# S1C31D50 register map
Vendor: Epson; Series: S1C31D50; File version: 1.00
CPU: CM0PLUS r0p1, little endian, MPU, no FPU, VTOR, 2 interrupt priority bits
Registers are 16-bit, read-write, reset 0x0 unless marked. A register's access mark holds for its fields unless they carry their own. Offsets are from the block's base; [hi:lo] are bit positions; {n}, {i} and the like mark numbered series; 'fields as' and 'values as' point back to an identical list.

## SPIA_0 — Synchronous serial interface control
Base 0x002003B0
Same registers: SPIA_2 0x002004D0, SPIA_1 0x00200670
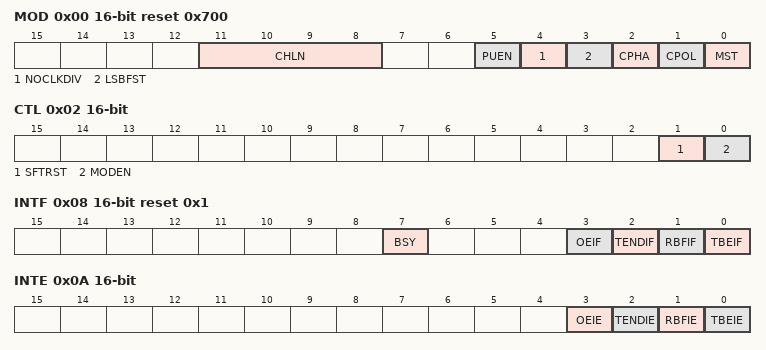
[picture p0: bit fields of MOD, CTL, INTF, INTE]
0x00 MOD reset 0x700 — Mode Register
  [11:8] CHLN — Data length select
    {v}={v+1}_BITS (v=1..15)
  [5] PUEN — #SPISS, SPICLK (input), SDI pull-up, pull-down enable
    0=DISABLE (Disable pull-up/down); 1=ENABLE (Enable pull-up/down)
  [4] NOCLKDIV — No USE T16 underflow pulse
    0=USE_T16; 1=NO_USE_T16
  [3] LSBFST — LSB first mode select
    0=MSB_FIRST; 1=LSB_FIRST
  [2] CPHA — Clock phase select
  [1] CPOL — Clock polarity select
  [0] MST — Master mode select
    0=SLAVE (Slave mode); 1=MASTER (Master mode)
0x02 CTL — Control Register
  [1] SFTRST write-1-sets — Soft reset
    on write: 0=NON (No effect); 1=RESET (Issue software reset) | on read: 0=STOPPED (Software reset has finished (During normal operation)); 1=RUNNING (Software reset is executing)
  [0] MODEN — SPI enable
    0=DISABLE (Disable SPIA operations (In master mode, the operating clock is stopped)); 1=ENABLE (Enable SPIA operations (In master mode, the operating clock is supplied))
0x04 TXD — Transmit Data Register
  [15:0] TXD — Transmit buffer
0x06 RXD ro — Receive Data Register
  [15:0] RXD — Receive buffer
0x08 INTF reset 0x1 — Interrupt Flag Register
  [7] BSY ro — Transfer Busy / Slave Selected
    0=IDLE; 1=BUSY (Transmit/receive busy (master mode), #SPISSn = Low level (slave mode))
  [3] OEIF write-1-clears — Receive over write error flag
    0=NOT_OCCURED (No cause of interrupt occurred); 1=OCCURED (Cause of interrupt occurred)
  [2] TENDIF write-1-clears — Transfer End interrupt flag
    values as OEIF
  [1] RBFIF ro — Receive buffer full interrupt flag (Cleared by reading the SPIAnRXD register)
    values as OEIF
  [0] TBEIF ro — Transmit buffer empty interrupt flag (Cleared by reading the SPIAnTXD register)
    values as OEIF
0x0A INTE — Interrupt Enable Register
  [all] fields
    0=DISABLE; 1=ENABLE
  [3] OEIE — Receive over write error interrupt enable
  [2] TENDIE — Transfer end interrupt enable
  [1] RBFIE — Receive buffer full interrupt enable
  [0] TBEIE — Transmit buffer empty interrupt enable
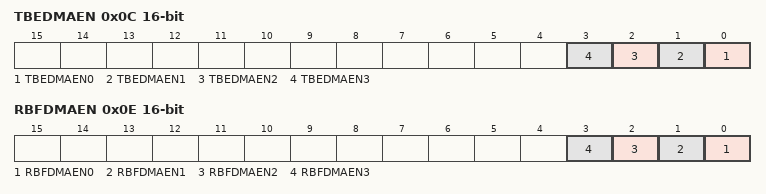
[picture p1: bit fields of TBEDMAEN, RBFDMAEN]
0x0C TBEDMAEN — TBE DMA Enable Register
  [all] fields
    0=DISABLE; 1=ENABLE
  [n] TBEDMAEN{n} (n=0..3) — TBE DMA ch{n} request enable
0x0E RBFDMAEN — RBF DMA Enable Register
  [all] fields
    0=DISABLE; 1=ENABLE
  [n] RBFDMAEN{n} (n=0..3) — RBF DMA ch{n} request enable

## SVD3 — Supply voltage detector control
Base 0x00200100
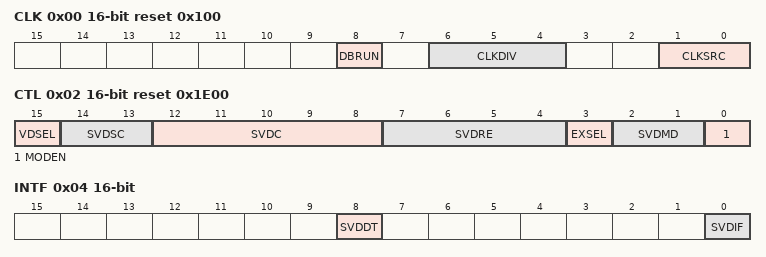
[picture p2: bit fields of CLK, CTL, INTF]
0x00 CLK reset 0x100 — SVD Clock Control Register
  [8] DBRUN — Enable clock on debug mode (can be write protected)
    0=DISABLE; 1=ENABLE
  [6:4] CLKDIV — Clock division select (can be write protected)
  [1:0] CLKSRC — Clock source select (can be write protected)
    0=IOSC; 1=OSC1; 2=OSC3; 3=EXOSC
0x02 CTL reset 0x1E00 — SVD Control Register
  [15] VDSEL — Voltage source select (can be write protected)
    0=VDD (Select VDD); 1=EXSVD (Select EXSVD)
  [14:13] SVDSC — Condition in intermittent operation mode(can be write protected). Writing take effect when the SVDCTL.SVDMD[1:0] bits are not 0x0
    0=1TIME (1 time in a row); 1=2TIMES (2 times in a row); 2=4TIMES (4 times in a row); 3=8TIMES (8 times in a row)
  [12:8] SVDC — SVD compare voltage (can be write protected).
  [7:4] SVDRE — SVD reset enable(can be write protected).
    10=ENABLE
  [3] EXSEL — EXSVD channel select(can be write protected).
    0=CH0 (Channel 0); 1=CH1 (Channel 1)
  [2:1] SVDMD — SVD intermittent mode
    0=Continuous intermittent mode; 1=128MSEC (SVDCLK/128); 2=256MSEC (SVDCLK/256); 3=512MSEC (SVDCLK/512)
  [0] MODEN — SVD enable
    0=Disable SVD; 1=Enable SVD
0x04 INTF — Status and Interrupt Flag Register
  [8] SVDDT ro — SVD detection monitor
    0=NOT_DETECTED (Power supply voltage (VDD or EXSVD) compare condition not detected); 1=DETECTED (Power supply voltage (VDD or EXSVD) compare condition detected)
  [0] SVDIF write-1-clears — SVD interrupt flag
    0=NOT_OCCURED (No cause of interrupt occurred); 1=OCCURED (Cause of interrupt occurred)
0x06 INTE — Interrupt Enable Register
  [0] SVDIE — SVD interrupt enable
    0=DISABLE; 1=ENABLE
